AUTOSAR XML (schema 314)
package /ComponentType
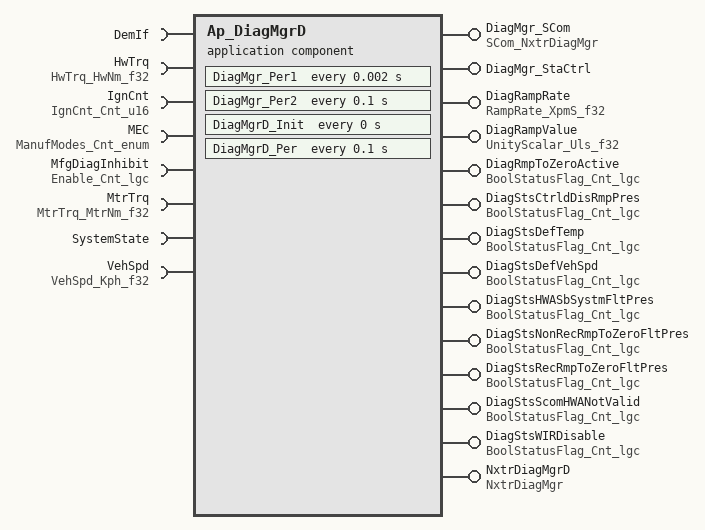
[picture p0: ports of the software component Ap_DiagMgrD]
  application software component type Ap_DiagMgrD
    14 x provide port:
      DiagMgr_SCom: provided-interface=SCom_NxtrDiagMgr
        provided-com-specs:
          operation=ClearBlackBox, queue-length=1
          operation=GetNTCInfo, queue-length=1
          operation=ReadStrgArray, queue-length=1
          operation=ResetNTCStatus, queue-length=1
      DiagMgr_StaCtrl: server-com-spec{operation=Shutdown, queue-length=1}, provided-interface=DiagMgr_StaCtrl
      DiagRampRate: unqueued-sender-com-spec{data-element=XpmS_f32, can-invalidate=false, init-value=D_ZERO_ULS_F32}, provided-interface=RampRate_XpmS_f32
      DiagRampValue: unqueued-sender-com-spec{data-element=Uls_f32, can-invalidate=false, init-value=D_ZERO_ULS_F32}, provided-interface=UnityScalar_Uls_f32
      DiagRmpToZeroActive: unqueued-sender-com-spec{data-element=Cnt_lgc, can-invalidate=false, init-value=D_FALSE_CNT_LGC}, provided-interface=BoolStatusFlag_Cnt_lgc
      DiagStsCtrldDisRmpPres: unqueued-sender-com-spec{data-element=Cnt_lgc, can-invalidate=false, init-value=D_FALSE_CNT_LGC}, provided-interface=BoolStatusFlag_Cnt_lgc
      DiagStsDefTemp: unqueued-sender-com-spec{data-element=Cnt_lgc, can-invalidate=false, init-value=D_FALSE_CNT_LGC}, provided-interface=BoolStatusFlag_Cnt_lgc
      DiagStsDefVehSpd: unqueued-sender-com-spec{data-element=Cnt_lgc, can-invalidate=false, init-value=D_FALSE_CNT_LGC}, provided-interface=BoolStatusFlag_Cnt_lgc
      DiagStsHWASbSystmFltPres: unqueued-sender-com-spec{data-element=Cnt_lgc, can-invalidate=false, init-value=D_FALSE_CNT_LGC}, provided-interface=BoolStatusFlag_Cnt_lgc
      DiagStsNonRecRmpToZeroFltPres: unqueued-sender-com-spec{data-element=Cnt_lgc, can-invalidate=false, init-value=D_FALSE_CNT_LGC}, provided-interface=BoolStatusFlag_Cnt_lgc
      DiagStsRecRmpToZeroFltPres: unqueued-sender-com-spec{data-element=Cnt_lgc, can-invalidate=false, init-value=D_FALSE_CNT_LGC}, provided-interface=BoolStatusFlag_Cnt_lgc
      DiagStsScomHWANotValid: unqueued-sender-com-spec{data-element=Cnt_lgc, can-invalidate=false, init-value=D_FALSE_CNT_LGC}, provided-interface=BoolStatusFlag_Cnt_lgc
      DiagStsWIRDisable: unqueued-sender-com-spec{data-element=Cnt_lgc, can-invalidate=false, init-value=D_FALSE_CNT_LGC}, provided-interface=BoolStatusFlag_Cnt_lgc
      NxtrDiagMgrD: provided-interface=NxtrDiagMgr
        provided-com-specs:
          operation=GetNTCActive, queue-length=1
          operation=GetNTCFailed, queue-length=1
          operation=GetNTCStatus, queue-length=1
          operation=SetNTCStatus, queue-length=1
    8 x require port:
      DemIf: required-com-specs=[DemShutdown, RestartDem, SetEventStatus, SetOperationCycleState], required-interface=DemIf
      HwTrq: unqueued-receiver-com-spec{data-element=HwNm_f32, init-value=D_ZERO_ULS_F32}, required-interface=HwTrq_HwNm_f32
      IgnCnt: unqueued-receiver-com-spec{data-element=Cnt_u16, init-value=D_ZERO_CNT_U16}, required-interface=IgnCnt_Cnt_u16
      MEC: unqueued-receiver-com-spec{data-element=Cnt_enum, init-value=D_MANUFMODEINIT_CNT_ENUM}, required-interface=ManufModes_Cnt_enum
      MfgDiagInhibit: unqueued-receiver-com-spec{data-element=Cnt_lgc, init-value=D_FALSE_CNT_LGC}, required-interface=Enable_Cnt_lgc
      MtrTrq: unqueued-receiver-com-spec{data-element=MtrNm_f32, init-value=D_ZERO_ULS_F32}, required-interface=MtrTrq_MtrNm_f32
      SystemState: required-interface=SystemState
      VehSpd: unqueued-receiver-com-spec{data-element=Kph_f32, init-value=D_ZERO_ULS_F32}, required-interface=VehSpd_Kph_f32
  internal behavior Ap_DiagMgrD_InternalBehavior: component=Ap_DiagMgrD
    timing event TMT_DiagMgr_Per1: start-on-event=DiagMgr_Per1, period=0.002
    timing event TMT_DiagMgr_Per2: mode-dependency=dependent-on-mode=SystemState.Mode.OFF, start-on-event=DiagMgr_Per2, period=0.1
    5 x operation invoked event:
      OIT_DiagMgr_SCom_ClearBlackBox_DiagMgr_SCom_ClearBlackBox: start-on-event=DiagMgr_SCom_ClearBlackBox, operation=DiagMgr_SCom.ClearBlackBox
      OIT_DiagMgr_SCom_GetNTCInfo_DiagMgr_SCom_GetNTCInfo: start-on-event=DiagMgr_SCom_GetNTCInfo, operation=DiagMgr_SCom.GetNTCInfo
      OIT_DiagMgr_SCom_ReadStrgArray_DiagMgr_SCom_ReadStrgArray: start-on-event=DiagMgr_SCom_ReadStrgArray, operation=DiagMgr_SCom.ReadStrgArray
      OIT_DiagMgr_SCom_ResetNTCStatus_DiagMgr_SCom_ResetNTCStatus: start-on-event=DiagMgr_SCom_ResetNTCStatus, operation=DiagMgr_SCom.ResetNTCStatus
      OIT_DiagMgr_StaCtrl_Shutdown_DiagMgr_StaCtrl_Shutdown: start-on-event=DiagMgr_StaCtrl_Shutdown, operation=DiagMgr_StaCtrl.Shutdown
    mode switch event MST_DiagMgr_Trns1_0: start-on-event=DiagMgr_Trns1, activation=EXIT, mode=SystemState.Mode.OFF
    timing event DiagMgrD_InitEvent: start-on-event=DiagMgrD_Init, period=0
    timing event TMT_DiagMgrD_Per: start-on-event=DiagMgrD_Per, period=0.1
    mode switch event MST_DiagMgrD_Trns_0: start-on-event=DiagMgrD_Trns, activation=EXIT, mode=SystemState.Mode.OFF
    4 x operation invoked event:
      OIT_NxtrDiagMgrD_GetNTCActive_NxtrDiagMgrD_GetNTCActive: start-on-event=NxtrDiagMgrD_GetNTCActive, operation=NxtrDiagMgrD.GetNTCActive
      OIT_NxtrDiagMgrD_GetNTCFailed_NxtrDiagMgrD_GetNTCFailed: start-on-event=NxtrDiagMgrD_GetNTCFailed, operation=NxtrDiagMgrD.GetNTCFailed
      OIT_NxtrDiagMgrD_GetNTCStatus_NxtrDiagMgrD_GetNTCStatus: start-on-event=NxtrDiagMgrD_GetNTCStatus, operation=NxtrDiagMgrD.GetNTCStatus
      OIT_NxtrDiagMgrD_SetNTCStatus_NxtrDiagMgrD_SetNTCStatus: start-on-event=NxtrDiagMgrD_SetNTCStatus, operation=NxtrDiagMgrD.SetNTCStatus
    port-api-options:
      enable-take-address=false, indirect-api=false, port=DemIf
      enable-take-address=false, indirect-api=false, port=DiagMgr_SCom
      enable-take-address=false, indirect-api=false, port=DiagMgr_StaCtrl
      enable-take-address=false, indirect-api=false, port=DiagRampRate
      enable-take-address=false, indirect-api=false, port=DiagRampValue
      enable-take-address=false, indirect-api=false, port=DiagRmpToZeroActive
      enable-take-address=false, indirect-api=false, port=DiagStsCtrldDisRmpPres
      enable-take-address=false, indirect-api=false, port=DiagStsDefTemp
      enable-take-address=false, indirect-api=false, port=DiagStsDefVehSpd
      enable-take-address=false, indirect-api=false, port=DiagStsHWASbSystmFltPres
      enable-take-address=false, indirect-api=false, port=DiagStsNonRecRmpToZeroFltPres
      enable-take-address=false, indirect-api=false, port=DiagStsRecRmpToZeroFltPres
      enable-take-address=false, indirect-api=false, port=DiagStsScomHWANotValid
      enable-take-address=false, indirect-api=false, port=DiagStsWIRDisable
      enable-take-address=false, indirect-api=false, port=HwTrq
      enable-take-address=false, indirect-api=false, port=IgnCnt
      enable-take-address=false, indirect-api=false, port=MEC
      enable-take-address=false, indirect-api=false, port=MfgDiagInhibit
      enable-take-address=false, indirect-api=false, port=MtrTrq
      enable-take-address=false, indirect-api=false, port=NxtrDiagMgrD
      enable-take-address=false, indirect-api=false, port=SystemState
      enable-take-address=false, indirect-api=false, port=VehSpd
    15 x runnable:
      DiagMgr_Per1
        11 x data send point:
          SEND_DiagRampRate_XpmS_f32: data-element=DiagRampRate.XpmS_f32
          SEND_DiagRampValue_Uls_f32: data-element=DiagRampValue.Uls_f32
          SEND_DiagRmpToZeroActive_Cnt_lgc: data-element=DiagRmpToZeroActive.Cnt_lgc
          SEND_DiagStsCtrldDisRmpPres_Cnt_lgc: data-element=DiagStsCtrldDisRmpPres.Cnt_lgc
          SEND_DiagStsDefTemp_Cnt_lgc: data-element=DiagStsDefTemp.Cnt_lgc
          SEND_DiagStsDefVehSpd_Cnt_lgc: data-element=DiagStsDefVehSpd.Cnt_lgc
          SEND_DiagStsHWASbSystmFltPres_Cnt_lgc: data-element=DiagStsHWASbSystmFltPres.Cnt_lgc
          SEND_DiagStsNonRecRmpToZeroFltPres_Cnt_lgc: data-element=DiagStsNonRecRmpToZeroFltPres.Cnt_lgc
          SEND_DiagStsRecRmpToZeroFltPres_Cnt_lgc: data-element=DiagStsRecRmpToZeroFltPres.Cnt_lgc
          SEND_DiagStsScomHWANotValid_Cnt_lgc: data-element=DiagStsScomHWANotValid.Cnt_lgc
          SEND_DiagStsWIRDisable_Cnt_lgc: data-element=DiagStsWIRDisable.Cnt_lgc
      DiagMgr_Per2
        sync call SC_DemIf_SetEventStatus: operation=DemIf.SetEventStatus, timeout=0
      DiagMgr_SCom_ClearBlackBox
      DiagMgr_SCom_GetNTCInfo
      DiagMgr_SCom_ReadStrgArray
      DiagMgr_SCom_ResetNTCStatus
      DiagMgr_StaCtrl_Shutdown
        sync call SC_DemIf_DemShutdown: operation=DemIf.DemShutdown, timeout=0
      DiagMgr_Trns1
        sync call SC_DemIf_RestartDem: operation=DemIf.RestartDem, timeout=0
        sync call SC_DemIf_SetOperationCycleState: operation=DemIf.SetOperationCycleState, timeout=0
      DiagMgrD_Init
        sync call SC_DemIf_SetOperationCycleState: operation=DemIf.SetOperationCycleState, timeout=0
      DiagMgrD_Per
      DiagMgrD_Trns
      NxtrDiagMgrD_GetNTCActive: can-be-invoked-concurrently=true
      NxtrDiagMgrD_GetNTCFailed: can-be-invoked-concurrently=true
      NxtrDiagMgrD_GetNTCStatus: can-be-invoked-concurrently=true
      NxtrDiagMgrD_SetNTCStatus: can-be-invoked-concurrently=true
        6 x data receive point:
          REC_HwTrq_HwNm_f32: data-element=HwTrq.HwNm_f32
          REC_IgnCnt_Cnt_u16: data-element=IgnCnt.Cnt_u16
          REC_MEC_Cnt_enum: data-element=MEC.Cnt_enum
          REC_MfgDiagInhibit_Cnt_lgc: data-element=MfgDiagInhibit.Cnt_lgc
          REC_MtrTrq_MtrNm_f32: data-element=MtrTrq.MtrNm_f32
          REC_VehSpd_Kph_f32: data-element=VehSpd.Kph_f32
  swc implementation Ap_DiagMgrD_Implementation: behavior=Ap_DiagMgrD_InternalBehavior
    code-descriptors:
      code Code: type=SRC
